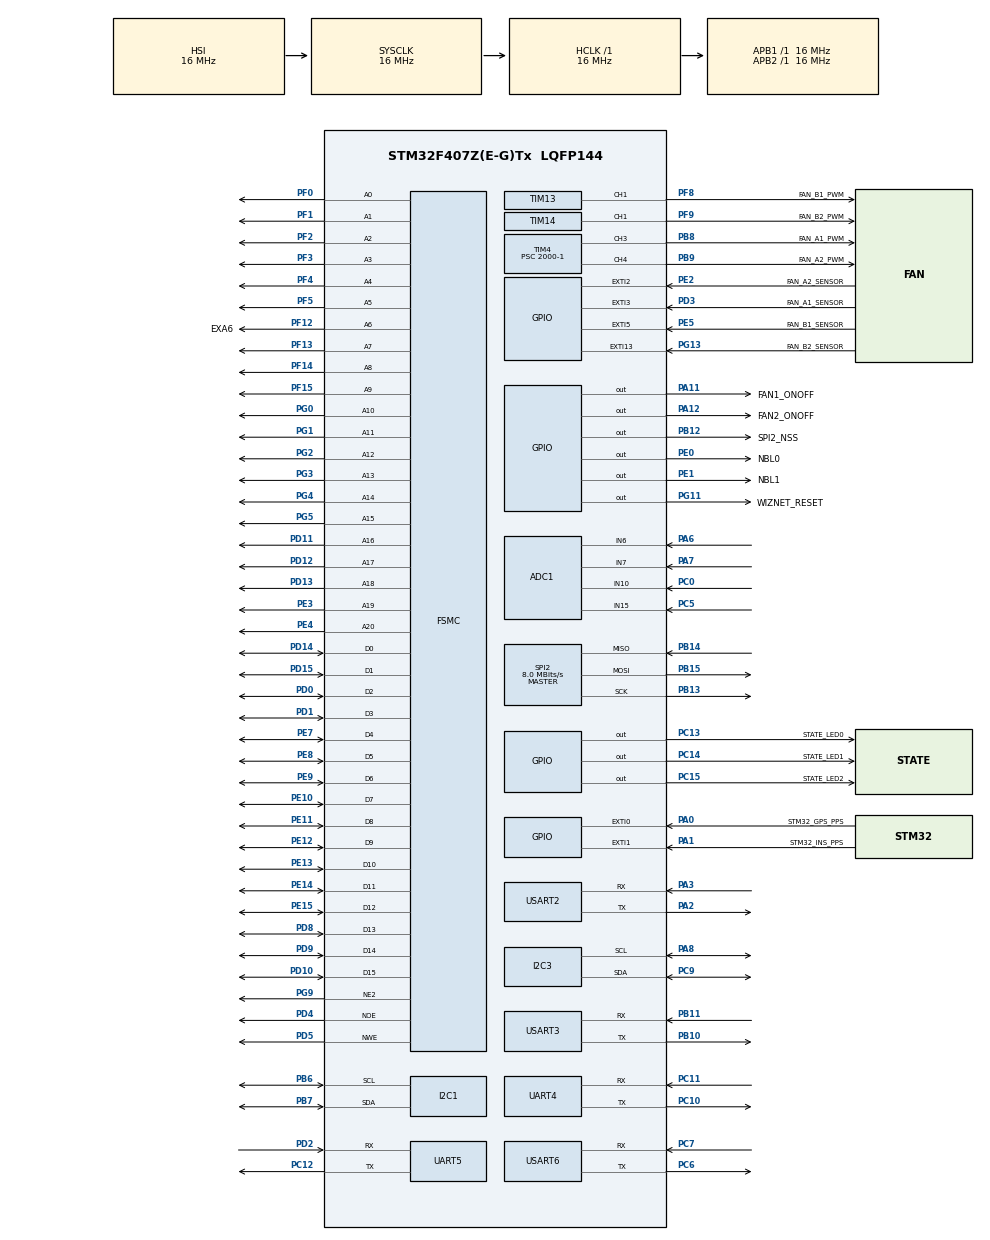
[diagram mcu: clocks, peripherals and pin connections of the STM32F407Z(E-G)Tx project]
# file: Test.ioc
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ADC1.Channel-0\#ChannelRegularConversion=ADC_CHANNEL_TEMPSENSOR
ADC1.Channel-1\#ChannelRegularConversion=ADC_CHANNEL_6
ADC1.Channel-2\#ChannelRegularConversion=ADC_CHANNEL_7
ADC1.Channel-3\#ChannelRegularConversion=ADC_CHANNEL_10
ADC1.Channel-4\#ChannelRegularConversion=ADC_CHANNEL_15
ADC1.ContinuousConvMode=DISABLE
ADC1.DMAContinuousRequests=ENABLE
ADC1.DiscontinuousConvMode=ENABLE
ADC1.NbrOfConversion=5
ADC1.NbrOfConversionFlag=1
ADC1.Rank-0\#ChannelRegularConversion=1
ADC1.Rank-1\#ChannelRegularConversion=2
ADC1.Rank-2\#ChannelRegularConversion=3
ADC1.Rank-3\#ChannelRegularConversion=4
ADC1.Rank-4\#ChannelRegularConversion=5
ADC1.SamplingTime-0\#ChannelRegularConversion=ADC_SAMPLETIME_3CYCLES
ADC1.SamplingTime-1\#ChannelRegularConversion=ADC_SAMPLETIME_3CYCLES
ADC1.SamplingTime-2\#ChannelRegularConversion=ADC_SAMPLETIME_3CYCLES
ADC1.SamplingTime-3\#ChannelRegularConversion=ADC_SAMPLETIME_3CYCLES
ADC1.SamplingTime-4\#ChannelRegularConversion=ADC_SAMPLETIME_3CYCLES
ADC1.ScanConvMode=ENABLE
ADC1.master=1
Dma.ADC1.0.Direction=DMA_PERIPH_TO_MEMORY
Dma.ADC1.0.FIFOMode=DMA_FIFOMODE_DISABLE
Dma.ADC1.0.Instance=DMA2_Stream0
Dma.ADC1.0.MemDataAlignment=DMA_MDATAALIGN_WORD
Dma.ADC1.0.MemInc=DMA_MINC_ENABLE
Dma.ADC1.0.Mode=DMA_CIRCULAR
Dma.ADC1.0.PeriphDataAlignment=DMA_PDATAALIGN_WORD
Dma.ADC1.0.PeriphInc=DMA_PINC_DISABLE
Dma.ADC1.0.Priority=DMA_PRIORITY_LOW
Dma.Request0=ADC1
FSMC.AddressSetupTime2=0
FSMC.BusTurnAroundDuration2=0
FSMC.DataSetupTime2=3
FSMC.WriteOperation2=FSMC_WRITE_OPERATION_ENABLE
I2C1.I2C_Mode=I2C_Standard
Mcu.Family=STM32F4
Mcu.Name=STM32F407Z(E-G)Tx
Mcu.Package=LQFP144
NVIC.DMA2_Stream0_IRQn=true\:0\:0\:false\:false\:true\:false\:true\:true
NVIC.EXTI15_10_IRQn=true\:0\:0\:false\:false\:true\:true\:true\:true
NVIC.EXTI2_IRQn=true\:0\:0\:false\:false\:true\:true\:true\:true
NVIC.EXTI3_IRQn=true\:0\:0\:false\:false\:true\:true\:true\:true
NVIC.EXTI9_5_IRQn=true\:0\:0\:false\:false\:true\:true\:true\:true
NVIC.PriorityGroup=NVIC_PRIORITYGROUP_4
NVIC.USART2_IRQn=true\:0\:0\:false\:false\:true\:true\:true\:true
PA0-WKUP.GPIO_Label=STM32_GPS_PPS
PA0-WKUP.Signal=GPXTI0
PA1.GPIO_Label=STM32_INS_PPS
PA1.Signal=GPXTI1
PA11.GPIO_Label=FAN1_ONOFF
PA11.Signal=GPIO_Output
PA12.GPIO_Label=FAN2_ONOFF
PA12.Signal=GPIO_Output
PA13.Mode=JTAG_5_pins
PA13.Signal=SYS_JTMS-SWDIO
PA14.Mode=JTAG_5_pins
PA14.Signal=SYS_JTCK-SWCLK
PA15.Mode=JTAG_5_pins
PA15.Signal=SYS_JTDI
PA2.Mode=Asynchronous
PA2.Signal=USART2_TX
PA3.Mode=Asynchronous
PA3.Signal=USART2_RX
PA6.Signal=ADCx_IN6
PA7.Signal=ADCx_IN7
PA8.GPIO_Pu=GPIO_PULLUP
PA8.Mode=I2C
PA8.Signal=I2C3_SCL
PB10.Mode=Asynchronous
PB10.Signal=USART3_TX
PB11.Mode=Asynchronous
PB11.Signal=USART3_RX
PB12.GPIO_Label=SPI2_NSS
PB12.Signal=GPIO_Output
PB13.Mode=Full_Duplex_Master
PB13.Signal=SPI2_SCK
PB14.Mode=Full_Duplex_Master
PB14.Signal=SPI2_MISO
PB15.Mode=Full_Duplex_Master
PB15.Signal=SPI2_MOSI
PB3.Mode=JTAG_5_pins
PB3.Signal=SYS_JTDO-SWO
PB4.Mode=JTAG_5_pins
PB4.Signal=SYS_JTRST
PB6.GPIO_Pu=GPIO_PULLUP
PB6.Mode=I2C
PB6.Signal=I2C1_SCL
PB7.GPIO_Pu=GPIO_PULLUP
PB7.Mode=I2C
PB7.Signal=I2C1_SDA
PB8.GPIO_Label=FAN_A1_PWM
PB8.Signal=S_TIM4_CH3
PB9.GPIO_Label=FAN_A2_PWM
PB9.Signal=S_TIM4_CH4
PC0.Signal=ADCx_IN10
PC10.Mode=Asynchronous
PC10.Signal=UART4_TX
PC11.Mode=Asynchronous
PC11.Signal=UART4_RX
PC12.Mode=Asynchronous
PC12.Signal=UART5_TX
PC13-ANTI_TAMP.GPIO_Label=STATE_LED0
PC13-ANTI_TAMP.Signal=GPIO_Output
PC14-OSC32_IN.GPIO_Label=STATE_LED1
PC14-OSC32_IN.Signal=GPIO_Output
PC15-OSC32_OUT.GPIO_Label=STATE_LED2
PC15-OSC32_OUT.Signal=GPIO_Output
PC5.Signal=ADCx_IN15
PC6.Mode=Asynchronous
PC6.Signal=USART6_TX
PC7.Mode=Asynchronous
PC7.Signal=USART6_RX
PC9.GPIO_Pu=GPIO_PULLUP
PC9.Mode=I2C
PC9.Signal=I2C3_SDA
PD0.Signal=FSMC_D2_DA2
PD1.Signal=FSMC_D3_DA3
PD10.Signal=FSMC_D15_DA15
PD11.Signal=FSMC_A16_CLE
PD12.Signal=FSMC_A17_ALE
PD13.Signal=FSMC_A18
PD14.Signal=FSMC_D0_DA0
PD15.Signal=FSMC_D1_DA1
PD2.Mode=Asynchronous
PD2.Signal=UART5_RX
PD3.GPIO_Label=FAN_A1_SENSOR
PD3.Signal=GPXTI3
PD4.Signal=FSMC_NOE
PD5.Signal=FSMC_NWE
PD8.Signal=FSMC_D13_DA13
PD9.Signal=FSMC_D14_DA14
PE0.GPIO_Label=NBL0
PE0.Signal=GPIO_Output
PE1.GPIO_Label=NBL1
PE1.Signal=GPIO_Output
PE10.Signal=FSMC_D7_DA7
PE11.Signal=FSMC_D8_DA8
PE12.Signal=FSMC_D9_DA9
PE13.Signal=FSMC_D10_DA10
PE14.Signal=FSMC_D11_DA11
PE15.Signal=FSMC_D12_DA12
PE2.GPIO_Label=FAN_A2_SENSOR
PE2.Signal=GPXTI2
PE3.Signal=FSMC_A19
PE4.Signal=FSMC_A20
PE5.GPIO_Label=FAN_B1_SENSOR
PE5.Signal=GPXTI5
PE7.Signal=FSMC_D4_DA4
PE8.Signal=FSMC_D5_DA5
PE9.Signal=FSMC_D6_DA6
PF0.Signal=FSMC_A0
PF1.Signal=FSMC_A1
PF12.GPIO_Label=EXA6
PF12.Signal=FSMC_A6
PF13.Signal=FSMC_A7
PF14.Signal=FSMC_A8
PF15.Signal=FSMC_A9
PF2.Signal=FSMC_A2
PF3.Signal=FSMC_A3
PF4.Signal=FSMC_A4
PF5.Signal=FSMC_A5
PF8.GPIO_Label=FAN_B1_PWM
PF8.Signal=S_TIM13_CH1
PF9.GPIO_Label=FAN_B2_PWM
PF9.Signal=S_TIM14_CH1
PG0.Signal=FSMC_A10
PG1.Signal=FSMC_A11
PG11.GPIO_Label=WIZNET_RESET
PG11.PinState=GPIO_PIN_SET
PG11.Signal=GPIO_Output
PG13.GPIO_Label=FAN_B2_SENSOR
PG13.Signal=GPXTI13
PG2.Signal=FSMC_A12
PG3.Signal=FSMC_A13
PG4.Signal=FSMC_A14
PG5.Signal=FSMC_A15
PG9.Mode=NorPsramChipSelect2_2
PG9.Signal=FSMC_NE2
PH0-OSC_IN.Mode=HSE-External-Oscillator
PH0-OSC_IN.Signal=RCC_OSC_IN
PH1-OSC_OUT.Mode=HSE-External-Oscillator
PH1-OSC_OUT.Signal=RCC_OSC_OUT
ProjectManager.HeapSize=0x200
ProjectManager.StackSize=0x400
ProjectManager.TargetToolchain=EWARM V8.32
RCC.48MHZClocksFreq_Value=32000000
RCC.AHBFreq_Value=16000000
RCC.APB1Freq_Value=16000000
RCC.APB1TimFreq_Value=16000000
RCC.APB2Freq_Value=16000000
RCC.APB2TimFreq_Value=16000000
RCC.CortexFreq_Value=16000000
RCC.HCLKFreq_Value=16000000
RCC.HSE_VALUE=25000000
RCC.HSI_VALUE=16000000
RCC.LSE_VALUE=32768
RCC.PLLM=8
RCC.PLLN=64
RCC.SYSCLKFreq_VALUE=16000000
RCC.VCOOutputFreq_Value=128000000
SH.ADCx_IN10.0=ADC1_IN10,IN10
SH.ADCx_IN15.0=ADC1_IN15,IN15
SH.ADCx_IN6.0=ADC1_IN6,IN6
SH.ADCx_IN7.0=ADC1_IN7,IN7
SH.FSMC_A0.0=FSMC_A0,21b-a2
SH.FSMC_A1.0=FSMC_A1,21b-a2
SH.FSMC_A10.0=FSMC_A10,21b-a2
SH.FSMC_A11.0=FSMC_A11,21b-a2
SH.FSMC_A12.0=FSMC_A12,21b-a2
SH.FSMC_A13.0=FSMC_A13,21b-a2
SH.FSMC_A14.0=FSMC_A14,21b-a2
SH.FSMC_A15.0=FSMC_A15,21b-a2
SH.FSMC_A16_CLE.0=FSMC_A16,21b-a2
SH.FSMC_A17_ALE.0=FSMC_A17,21b-a2
SH.FSMC_A18.0=FSMC_A18,21b-a2
SH.FSMC_A19.0=FSMC_A19,21b-a2
SH.FSMC_A2.0=FSMC_A2,21b-a2
SH.FSMC_A20.0=FSMC_A20,21b-a2
SH.FSMC_A3.0=FSMC_A3,21b-a2
SH.FSMC_A4.0=FSMC_A4,21b-a2
SH.FSMC_A5.0=FSMC_A5,21b-a2
SH.FSMC_A6.0=FSMC_A6,21b-a2
SH.FSMC_A7.0=FSMC_A7,21b-a2
SH.FSMC_A8.0=FSMC_A8,21b-a2
SH.FSMC_A9.0=FSMC_A9,21b-a2
SH.FSMC_D0_DA0.0=FSMC_D0,16b-d2
SH.FSMC_D10_DA10.0=FSMC_D10,16b-d2
SH.FSMC_D11_DA11.0=FSMC_D11,16b-d2
SH.FSMC_D12_DA12.0=FSMC_D12,16b-d2
SH.FSMC_D13_DA13.0=FSMC_D13,16b-d2
SH.FSMC_D14_DA14.0=FSMC_D14,16b-d2
SH.FSMC_D15_DA15.0=FSMC_D15,16b-d2
SH.FSMC_D1_DA1.0=FSMC_D1,16b-d2
SH.FSMC_D2_DA2.0=FSMC_D2,16b-d2
SH.FSMC_D3_DA3.0=FSMC_D3,16b-d2
SH.FSMC_D4_DA4.0=FSMC_D4,16b-d2
SH.FSMC_D5_DA5.0=FSMC_D5,16b-d2
SH.FSMC_D6_DA6.0=FSMC_D6,16b-d2
SH.FSMC_D7_DA7.0=FSMC_D7,16b-d2
SH.FSMC_D8_DA8.0=FSMC_D8,16b-d2
SH.FSMC_D9_DA9.0=FSMC_D9,16b-d2
SH.FSMC_NOE.0=FSMC_NOE,Sram2
SH.FSMC_NWE.0=FSMC_NWE,Sram2
SH.S_TIM13_CH1.0=TIM13_CH1,PWM Generation1 CH1
SH.S_TIM14_CH1.0=TIM14_CH1,PWM Generation1 CH1
SH.S_TIM4_CH3.0=TIM4_CH3,PWM Generation3 CH3
SH.S_TIM4_CH4.0=TIM4_CH4,PWM Generation4 CH4
SPI2.CalculateBaudRate=8.0 MBits/s
SPI2.Direction=SPI_DIRECTION_2LINES
SPI2.Mode=SPI_MODE_MASTER
SPI2.VirtualType=VM_MASTER
TIM13.Channel=TIM_CHANNEL_1
TIM13.Period=1000-1
TIM13.Prescaler=2000-1
TIM13.Pulse=900-1
TIM14.Channel=TIM_CHANNEL_1
TIM14.Period=1000-1
TIM14.Prescaler=2000-1
TIM14.Pulse=900-1
TIM4.Channel-PWM\ Generation3\ CH3=TIM_CHANNEL_3
TIM4.Channel-PWM\ Generation4\ CH4=TIM_CHANNEL_4
TIM4.Period=1000-1
TIM4.Prescaler=2000-1
TIM4.Pulse-PWM\ Generation3\ CH3=900-1
TIM4.Pulse-PWM\ Generation4\ CH4=900-1
TIM6.Period=1000-1
TIM6.Prescaler=16000-1
UART4.VirtualMode=Asynchronous
UART5.VirtualMode=Asynchronous
USART2.VirtualMode=VM_ASYNC
USART3.VirtualMode=VM_ASYNC
USART6.VirtualMode=VM_ASYNC
VP_ADC1_TempSens_Input.Mode=IN-TempSens
VP_TIM13_VS_ClockSourceINT.Mode=Enable_Timer
VP_TIM14_VS_ClockSourceINT.Mode=Enable_Timer
VP_TIM4_VS_ClockSourceINT.Mode=Internal
VP_TIM6_VS_ClockSourceINT.Mode=Enable_Timer
board=custom

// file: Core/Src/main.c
/* USER CODE BEGIN Header */
/**
******************************************************************************
* @file           : main.c
* @brief          : Main program body
******************************************************************************
* @attention
*
* Copyright (c) 2022 STMicroelectronics.
* All rights reserved.
*
* This software is licensed under terms that can be found in the LICENSE file
* in the root directory of this software component.
* If no LICENSE file comes with this software, it is provided AS-IS.
*
******************************************************************************
*/
/* USER CODE END Header */
#include "main.h"

/* USER CODE BEGIN Includes */
#include "math.h"
#include "stdio.h"
/* USER CODE END Includes */

/* USER CODE BEGIN PD */

#define TSYS01_ADDR                        0x77
#define TSYS01_RESET                       0x1E
#define TSYS01_ADC_READ                    0x00
#define TSYS01_ADC_TEMP_CONV               0x48
#define TSYS01_PROM_READ                   0XA0

#define RPM_Calculation                 60000

/* USER CODE END PD */

ADC_HandleTypeDef hadc1;
DMA_HandleTypeDef hdma_adc1;

I2C_HandleTypeDef hi2c1;
I2C_HandleTypeDef hi2c3;

SPI_HandleTypeDef hspi2;

TIM_HandleTypeDef htim4;
TIM_HandleTypeDef htim6;
TIM_HandleTypeDef htim13;
TIM_HandleTypeDef htim14;

UART_HandleTypeDef huart4;
UART_HandleTypeDef huart5;
UART_HandleTypeDef huart2;
UART_HandleTypeDef huart3;
UART_HandleTypeDef huart6;

SRAM_HandleTypeDef hsram2;

void SystemClock_Config(void);
static void MX_GPIO_Init(void);
static void MX_DMA_Init(void);
static void MX_I2C3_Init(void);
static void MX_UART4_Init(void);
static void MX_UART5_Init(void);
static void MX_USART2_UART_Init(void);
static void MX_USART3_UART_Init(void);
static void MX_USART6_UART_Init(void);
static void MX_SPI2_Init(void);
static void MX_I2C1_Init(void);
static void MX_TIM4_Init(void);
static void MX_FSMC_Init(void);
static void MX_TIM13_Init(void);
static void MX_TIM14_Init(void);
static void MX_TIM6_Init(void);
static void MX_ADC1_Init(void);

/* USER CODE BEGIN 0 */

//prinf() UART out
int fputc(int ch,  FILE *f){

  HAL_UART_Transmit(&huart2,(uint8_t*)&ch,1,1);

  return ch;

}

//temperature sensor
float temperature_f1 =0.0;
float temperature_f2 =0.0;

//uart
uint8_t USART_RX_FLAG = 0;
uint8_t temp_rx =0;

typedef struct{
  uint16_t TIMER_DATA1;
  uint16_t TIMER_DATA2;
  uint16_t TIMER_MINU;
  uint16_t FAN_RPM;
  uint8_t  RPM_check;
}TIMER_struct;

typedef struct{
  float ADC_TEMP_C;
  float ADC_FAN1_VOL;
  float ADC_FAN2_VOL;
  float ADC_3_3V_VOL;
  float ADC_12V2_VOL;
}ADC_CAL_struct;

ADC_CAL_struct ADC_cal;

TIMER_struct A1_DATA;
TIMER_struct A2_DATA;
TIMER_struct B1_DATA;
TIMER_struct B2_DATA;

void TIMER_struct_init(TIMER_struct* DATA){
  DATA->TIMER_DATA1=0;
  DATA->TIMER_DATA2=0;
  DATA->TIMER_MINU=0;
  DATA->FAN_RPM=0;
  DATA->RPM_check=1;

}

void TIMER_RPM(TIMER_struct* DATA){

  if(DATA->RPM_check == 1){
    DATA->TIMER_DATA1=htim6.Instance->CNT;
    DATA->RPM_check++;
  }
  else if (DATA->RPM_check == 2){
    DATA->RPM_check++;
  }
  else if (DATA->RPM_check == 3){
    DATA->TIMER_DATA2=htim6.Instance->CNT;

    if(DATA->TIMER_DATA2 < DATA->TIMER_DATA1) DATA->TIMER_DATA2+=1000;

    DATA->TIMER_MINU =  DATA->TIMER_DATA2 - DATA->TIMER_DATA1;
    DATA->FAN_RPM = RPM_Calculation / DATA->TIMER_MINU;

    DATA->RPM_check=1;
  }

}
uint8_t i2c_rx[4];
double TEST_I2C(){
  uint8_t i2c_tx= 0x00;

  HAL_I2C_Master_Transmit(&hi2c1,0x80,&i2c_tx,1,100);
  HAL_Delay(1000);
  HAL_I2C_Master_Transmit(&hi2c3,0x80,&i2c_tx,1,100);
  HAL_Delay(1000);
  return 0.0;
}
double I2C_Temperature(I2C_HandleTypeDef *hi2c){

  uint8_t adc_read[5]={0};
  uint8_t adc_k2[2]={0};
  uint8_t adc_k3[2]={0};
  uint8_t adc_k4[2]={0};
  uint8_t adc_k1[2]={0};
  uint8_t adc_k0[2]={0};

  uint16_t adc_Coefficient[5]={0};
  uint64_t adc_data=0;

  uint16_t adc_read_addr = TSYS01_ADC_READ;
  uint16_t adc_prom_read = TSYS01_PROM_READ;
  uint8_t adc_start_addr = TSYS01_ADC_TEMP_CONV;

  double temperature_d = 0.0;
  HAL_I2C_Master_Transmit(hi2c,TSYS01_ADDR<<1,&adc_start_addr,1,100);

  HAL_Delay(10);
  HAL_I2C_Mem_Read(hi2c,TSYS01_ADDR<<1,adc_read_addr,1,adc_read,3,100);
  HAL_Delay(10);
  adc_data = 0;
  adc_data = adc_read[0];
  adc_data = (adc_data << 8) | adc_read[1];
  adc_data = (adc_data << 8) | adc_read[2];

  adc_data= adc_data/256;

  HAL_I2C_Mem_Read(hi2c,TSYS01_ADDR<<1,adc_prom_read+2,1,adc_k4,2,100);
  HAL_Delay(10);

  HAL_I2C_Mem_Read(hi2c,TSYS01_ADDR<<1,adc_prom_read+4,1,adc_k3,2,100);
  HAL_Delay(10);

  HAL_I2C_Mem_Read(hi2c,TSYS01_ADDR<<1,adc_prom_read+6,1,adc_k2,2,100);
  HAL_Delay(10);

  HAL_I2C_Mem_Read(hi2c,TSYS01_ADDR<<1,adc_prom_read+8,1,adc_k1,2,100);
  HAL_Delay(10);

  HAL_I2C_Mem_Read(hi2c,TSYS01_ADDR<<1,adc_prom_read+10,1,adc_k0,2,100);
  HAL_Delay(10);

  adc_Coefficient[0] = (uint16_t)((adc_k4[0] << 8) + adc_k4[1]);
  adc_Coefficient[1] = (uint16_t)((adc_k3[0] << 8) + adc_k3[1]);
  adc_Coefficient[2] = (uint16_t)((adc_k2[0] << 8) + adc_k2[1]);
  adc_Coefficient[3] = (uint16_t)((adc_k1[0] << 8) + adc_k1[1]);
  adc_Coefficient[4] = (uint16_t)((adc_k0[0] << 8) + adc_k0[1]);

  temperature_d = ((-2)*adc_Coefficient[0]/pow(10,21)*pow(adc_data,4))\
    +((4)*adc_Coefficient[1]/pow(10,16)*pow(adc_data,3))\
      +((-2)*adc_Coefficient[2]/pow(10,11)*pow(adc_data,2))\
        +((1)*adc_Coefficient[3]/pow(10,6)*adc_data)\
          +((-1.5)*adc_Coefficient[4]/pow(10,2));

  return temperature_d;

}

void HAL_GPIO_EXTI_Callback(uint16_t GPIO_Pin){

  //FAN_A1_SENSOR
  if(GPIO_Pin == GPIO_PIN_3){
    HAL_GPIO_TogglePin(GPIOC,STATE_LED0_Pin);
    TIMER_RPM(&A1_DATA);

  }
  //FAN_A2_SENSOR
  else if(GPIO_Pin == GPIO_PIN_2){
    TIMER_RPM(&A2_DATA);

  }
  //FAN_B1_SENSOR
  else if(GPIO_Pin == GPIO_PIN_5){
    TIMER_RPM(&B1_DATA);

  }
  //FAN_B2_SENSOR
  else if(GPIO_Pin == GPIO_PIN_13){
    TIMER_RPM(&B2_DATA);

  }
}
void HAL_UART_RxCpltCallback(UART_HandleTypeDef *huart)
{

  // USART1 Rx Interrupt
  if (huart->Instance == USART2) {

    if(temp_rx == '1'){
      USART_RX_FLAG =1;
    }
    else if(temp_rx == '2'){
      USART_RX_FLAG = 2;
    }

    HAL_UART_Receive_IT(&huart2, &temp_rx, 1);
  }
}
void HAL_TIM_PeriodElapsedCallback(TIM_HandleTypeDef *htim){
  if(htim->Instance == TIM6){

  }
}

uint32_t adcVal[5];

uint8_t adcIndex=0;
uint8_t adc_conv_flag = 0;
float temp1;

void ADC_Calculation(){

  ADC_cal.ADC_TEMP_C   = ((((float)adcVal[0] * 3.3) / 4096) - 0.76)/0.0025 + 25.0;
  ADC_cal.ADC_FAN1_VOL = ((float)adcVal[1] * 3.3 / 4096);
  ADC_cal.ADC_FAN2_VOL = ((float)adcVal[2] * 3.3 / 4096);
  ADC_cal.ADC_3_3V_VOL = ((float)adcVal[3] * 3.3 / 4096);
  ADC_cal.ADC_12V2_VOL = ((float)adcVal[4] * 3.3 / 4096);

}
void HAL_ADC_ConvCpltCallback(ADC_HandleTypeDef* hadc)
{

  ADC_Calculation();

}

/* USER CODE END 0 */

int main(void)
{

  /* MCU Configuration--------------------------------------------------------*/

  /* Reset of all peripherals, Initializes the Flash interface and the Systick. */
  HAL_Init();

  /* Configure the system clock */
  SystemClock_Config();

  /* Initialize all configured peripherals */
  MX_GPIO_Init();
  MX_DMA_Init();
  MX_I2C3_Init();
  MX_UART4_Init();
  MX_UART5_Init();
  MX_USART2_UART_Init();
  MX_USART3_UART_Init();
  MX_USART6_UART_Init();
  MX_SPI2_Init();
  MX_I2C1_Init();
  MX_TIM4_Init();
  MX_FSMC_Init();
  MX_TIM13_Init();
  MX_TIM14_Init();
  MX_TIM6_Init();
  MX_ADC1_Init();
  /* USER CODE BEGIN 2 */
  HAL_UART_Receive_IT(&huart2, &temp_rx, 1);
  /* USER CODE END 2 */

  /* Infinite loop */
  /* USER CODE BEGIN WHILE */

  uint8_t i2c_reset = 0x1E;

  TIMER_struct_init(&A1_DATA);
  TIMER_struct_init(&A2_DATA);
  TIMER_struct_init(&B1_DATA);
  TIMER_struct_init(&B2_DATA);

  // FAN2 Connecter start
  HAL_TIM_PWM_Start(&htim14, TIM_CHANNEL_1);
  HAL_TIM_PWM_Start(&htim13, TIM_CHANNEL_1);

  HAL_GPIO_WritePin(GPIOA,FAN2_ONOFF_Pin,GPIO_PIN_SET);

  //FAN1 Connecter start
  HAL_TIM_PWM_Start(&htim4, TIM_CHANNEL_3);
  HAL_TIM_PWM_Start(&htim4, TIM_CHANNEL_4);

  HAL_GPIO_WritePin(GPIOA,FAN1_ONOFF_Pin,GPIO_PIN_SET);

  //rpm data calculation timer
  HAL_TIM_Base_Start_IT(&htim6) ;

  //HAL_I2C_Master_Transmit(&hi2c3,TSYS01_ADDR<<1,&i2c_reset,1,100);
  HAL_Delay(10);

  while (1)
  {

    HAL_ADC_Start_DMA(&hadc1,adcVal,5);

    //temperature_f1 = I2C_Temperature(&hi2c3);
    temperature_f2 = TEST_I2C();

    if(temperature_f1 > 30){
      htim4.Instance->CCR3 = 500-1;
      htim4.Instance->CCR4 = 500-1;
    }
    else {
      htim4.Instance->CCR3 = 900-1;
      htim4.Instance->CCR4 = 900-1;
    }

    if(USART_RX_FLAG == 1){
      printf("$TEMP,1,%.2f,2,%.2f,uart,0\r\n",temperature_f1,temperature_f2);
      printf("$RPM,A1,%d,A2,%d,B1,%d,B2,%d,uart,1\r\n",A1_DATA.FAN_RPM,A2_DATA.FAN_RPM,B1_DATA.FAN_RPM,B2_DATA.FAN_RPM);
      printf("$ADC,temp,%.2f,FAN1,%.2f,FAN2,%.2f,3.3V,%.2f,12V,%.2f,uart,3\r\n",ADC_cal.ADC_TEMP_C,\
                                                                                ADC_cal.ADC_FAN1_VOL,ADC_cal.ADC_FAN2_VOL,ADC_cal.ADC_3_3V_VOL,ADC_cal.ADC_12V2_VOL);
      HAL_Delay(1000);

    }
    else if(USART_RX_FLAG == 2){
      printf("temp : %5.1f \r\n",temp1);
      HAL_Delay(1000);

    }
    /* USER CODE END WHILE */

  }
}

void SystemClock_Config(void)
{
  RCC_OscInitTypeDef RCC_OscInitStruct = {0};
  RCC_ClkInitTypeDef RCC_ClkInitStruct = {0};

  /** Configure the main internal regulator output voltage
  */
  __HAL_RCC_PWR_CLK_ENABLE();
  __HAL_PWR_VOLTAGESCALING_CONFIG(PWR_REGULATOR_VOLTAGE_SCALE1);

  /** Initializes the RCC Oscillators according to the specified parameters
  * in the RCC_OscInitTypeDef structure.
  */
  RCC_OscInitStruct.OscillatorType = RCC_OSCILLATORTYPE_HSI;
  RCC_OscInitStruct.HSIState = RCC_HSI_ON;
  RCC_OscInitStruct.HSICalibrationValue = RCC_HSICALIBRATION_DEFAULT;
  RCC_OscInitStruct.PLL.PLLState = RCC_PLL_NONE;
  if (HAL_RCC_OscConfig(&RCC_OscInitStruct) != HAL_OK)
  {
    Error_Handler();
  }

  /** Initializes the CPU, AHB and APB buses clocks
  */
  RCC_ClkInitStruct.ClockType = RCC_CLOCKTYPE_HCLK|RCC_CLOCKTYPE_SYSCLK
                              |RCC_CLOCKTYPE_PCLK1|RCC_CLOCKTYPE_PCLK2;
  RCC_ClkInitStruct.SYSCLKSource = RCC_SYSCLKSOURCE_HSI;
  RCC_ClkInitStruct.AHBCLKDivider = RCC_SYSCLK_DIV1;
  RCC_ClkInitStruct.APB1CLKDivider = RCC_HCLK_DIV1;
  RCC_ClkInitStruct.APB2CLKDivider = RCC_HCLK_DIV1;

  if (HAL_RCC_ClockConfig(&RCC_ClkInitStruct, FLASH_LATENCY_0) != HAL_OK)
  {
    Error_Handler();
  }
}

static void MX_ADC1_Init(void)
{

  ADC_ChannelConfTypeDef sConfig = {0};

  /** Configure the global features of the ADC (Clock, Resolution, Data Alignment and number of conversion)
  */
  hadc1.Instance = ADC1;
  hadc1.Init.ClockPrescaler = ADC_CLOCK_SYNC_PCLK_DIV2;
  hadc1.Init.Resolution = ADC_RESOLUTION_12B;
  hadc1.Init.ScanConvMode = ENABLE;
  hadc1.Init.ContinuousConvMode = DISABLE;
  hadc1.Init.DiscontinuousConvMode = ENABLE;
  hadc1.Init.NbrOfDiscConversion = 1;
  hadc1.Init.ExternalTrigConvEdge = ADC_EXTERNALTRIGCONVEDGE_NONE;
  hadc1.Init.ExternalTrigConv = ADC_SOFTWARE_START;
  hadc1.Init.DataAlign = ADC_DATAALIGN_RIGHT;
  hadc1.Init.NbrOfConversion = 5;
  hadc1.Init.DMAContinuousRequests = ENABLE;
  hadc1.Init.EOCSelection = ADC_EOC_SINGLE_CONV;
  if (HAL_ADC_Init(&hadc1) != HAL_OK)
  {
    Error_Handler();
  }

  /** Configure for the selected ADC regular channel its corresponding rank in the sequencer and its sample time.
  */
  sConfig.Channel = ADC_CHANNEL_TEMPSENSOR;
  sConfig.Rank = 1;
  sConfig.SamplingTime = ADC_SAMPLETIME_3CYCLES;
  if (HAL_ADC_ConfigChannel(&hadc1, &sConfig) != HAL_OK)
  {
    Error_Handler();
  }

  /** Configure for the selected ADC regular channel its corresponding rank in the sequencer and its sample time.
  */
  sConfig.Channel = ADC_CHANNEL_6;
  sConfig.Rank = 2;
  if (HAL_ADC_ConfigChannel(&hadc1, &sConfig) != HAL_OK)
  {
    Error_Handler();
  }

  /** Configure for the selected ADC regular channel its corresponding rank in the sequencer and its sample time.
  */
  sConfig.Channel = ADC_CHANNEL_7;
  sConfig.Rank = 3;
  if (HAL_ADC_ConfigChannel(&hadc1, &sConfig) != HAL_OK)
  {
    Error_Handler();
  }

  /** Configure for the selected ADC regular channel its corresponding rank in the sequencer and its sample time.
  */
  sConfig.Channel = ADC_CHANNEL_10;
  sConfig.Rank = 4;
  if (HAL_ADC_ConfigChannel(&hadc1, &sConfig) != HAL_OK)
  {
    Error_Handler();
  }

  /** Configure for the selected ADC regular channel its corresponding rank in the sequencer and its sample time.
  */
  sConfig.Channel = ADC_CHANNEL_15;
  sConfig.Rank = 5;
  if (HAL_ADC_ConfigChannel(&hadc1, &sConfig) != HAL_OK)
  {
    Error_Handler();
  }

}

static void MX_I2C1_Init(void)
{

  hi2c1.Instance = I2C1;
  hi2c1.Init.ClockSpeed = 100000;
  hi2c1.Init.DutyCycle = I2C_DUTYCYCLE_2;
  hi2c1.Init.OwnAddress1 = 0;
  hi2c1.Init.AddressingMode = I2C_ADDRESSINGMODE_7BIT;
  hi2c1.Init.DualAddressMode = I2C_DUALADDRESS_DISABLE;
  hi2c1.Init.OwnAddress2 = 0;
  hi2c1.Init.GeneralCallMode = I2C_GENERALCALL_DISABLE;
  hi2c1.Init.NoStretchMode = I2C_NOSTRETCH_DISABLE;
  if (HAL_I2C_Init(&hi2c1) != HAL_OK)
  {
    Error_Handler();
  }

}

static void MX_I2C3_Init(void)
{

  hi2c3.Instance = I2C3;
  hi2c3.Init.ClockSpeed = 100000;
  hi2c3.Init.DutyCycle = I2C_DUTYCYCLE_2;
  hi2c3.Init.OwnAddress1 = 0;
  hi2c3.Init.AddressingMode = I2C_ADDRESSINGMODE_7BIT;
  hi2c3.Init.DualAddressMode = I2C_DUALADDRESS_DISABLE;
  hi2c3.Init.OwnAddress2 = 0;
  hi2c3.Init.GeneralCallMode = I2C_GENERALCALL_DISABLE;
  hi2c3.Init.NoStretchMode = I2C_NOSTRETCH_DISABLE;
  if (HAL_I2C_Init(&hi2c3) != HAL_OK)
  {
    Error_Handler();
  }

}

static void MX_SPI2_Init(void)
{

  /* SPI2 parameter configuration*/
  hspi2.Instance = SPI2;
  hspi2.Init.Mode = SPI_MODE_MASTER;
  hspi2.Init.Direction = SPI_DIRECTION_2LINES;
  hspi2.Init.DataSize = SPI_DATASIZE_8BIT;
  hspi2.Init.CLKPolarity = SPI_POLARITY_LOW;
  hspi2.Init.CLKPhase = SPI_PHASE_1EDGE;
  hspi2.Init.NSS = SPI_NSS_SOFT;
  hspi2.Init.BaudRatePrescaler = SPI_BAUDRATEPRESCALER_2;
  hspi2.Init.FirstBit = SPI_FIRSTBIT_MSB;
  hspi2.Init.TIMode = SPI_TIMODE_DISABLE;
  hspi2.Init.CRCCalculation = SPI_CRCCALCULATION_DISABLE;
  hspi2.Init.CRCPolynomial = 10;
  if (HAL_SPI_Init(&hspi2) != HAL_OK)
  {
    Error_Handler();
  }

}

static void MX_TIM4_Init(void)
{

  TIM_ClockConfigTypeDef sClockSourceConfig = {0};
  TIM_MasterConfigTypeDef sMasterConfig = {0};
  TIM_OC_InitTypeDef sConfigOC = {0};

  htim4.Instance = TIM4;
  htim4.Init.Prescaler = 2000-1;
  htim4.Init.CounterMode = TIM_COUNTERMODE_UP;
  htim4.Init.Period = 1000-1;
  htim4.Init.ClockDivision = TIM_CLOCKDIVISION_DIV1;
  htim4.Init.AutoReloadPreload = TIM_AUTORELOAD_PRELOAD_DISABLE;
  if (HAL_TIM_Base_Init(&htim4) != HAL_OK)
  {
    Error_Handler();
  }
  sClockSourceConfig.ClockSource = TIM_CLOCKSOURCE_INTERNAL;
  if (HAL_TIM_ConfigClockSource(&htim4, &sClockSourceConfig) != HAL_OK)
  {
    Error_Handler();
  }
  if (HAL_TIM_PWM_Init(&htim4) != HAL_OK)
  {
    Error_Handler();
  }
  sMasterConfig.MasterOutputTrigger = TIM_TRGO_RESET;
  sMasterConfig.MasterSlaveMode = TIM_MASTERSLAVEMODE_DISABLE;
  if (HAL_TIMEx_MasterConfigSynchronization(&htim4, &sMasterConfig) != HAL_OK)
  {
    Error_Handler();
  }
  sConfigOC.OCMode = TIM_OCMODE_PWM1;
  sConfigOC.Pulse = 900-1;
  sConfigOC.OCPolarity = TIM_OCPOLARITY_HIGH;
  sConfigOC.OCFastMode = TIM_OCFAST_DISABLE;
  if (HAL_TIM_PWM_ConfigChannel(&htim4, &sConfigOC, TIM_CHANNEL_3) != HAL_OK)
  {
    Error_Handler();
  }
  if (HAL_TIM_PWM_ConfigChannel(&htim4, &sConfigOC, TIM_CHANNEL_4) != HAL_OK)
  {
    Error_Handler();
  }
  HAL_TIM_MspPostInit(&htim4);

}

static void MX_TIM6_Init(void)
{

  TIM_MasterConfigTypeDef sMasterConfig = {0};

  htim6.Instance = TIM6;
  htim6.Init.Prescaler = 16000-1;
  htim6.Init.CounterMode = TIM_COUNTERMODE_UP;
  htim6.Init.Period = 1000-1;
  htim6.Init.AutoReloadPreload = TIM_AUTORELOAD_PRELOAD_DISABLE;
  if (HAL_TIM_Base_Init(&htim6) != HAL_OK)
  {
    Error_Handler();
  }
  sMasterConfig.MasterOutputTrigger = TIM_TRGO_RESET;
  sMasterConfig.MasterSlaveMode = TIM_MASTERSLAVEMODE_DISABLE;
  if (HAL_TIMEx_MasterConfigSynchronization(&htim6, &sMasterConfig) != HAL_OK)
  {
    Error_Handler();
  }

}

static void MX_TIM13_Init(void)
{

  TIM_OC_InitTypeDef sConfigOC = {0};

  htim13.Instance = TIM13;
  htim13.Init.Prescaler = 2000-1;
  htim13.Init.CounterMode = TIM_COUNTERMODE_UP;
  htim13.Init.Period = 1000-1;
  htim13.Init.ClockDivision = TIM_CLOCKDIVISION_DIV1;
  htim13.Init.AutoReloadPreload = TIM_AUTORELOAD_PRELOAD_DISABLE;
  if (HAL_TIM_Base_Init(&htim13) != HAL_OK)
  {
    Error_Handler();
  }
  if (HAL_TIM_PWM_Init(&htim13) != HAL_OK)
  {
    Error_Handler();
  }
  sConfigOC.OCMode = TIM_OCMODE_PWM1;
  sConfigOC.Pulse = 900-1;
  sConfigOC.OCPolarity = TIM_OCPOLARITY_HIGH;
  sConfigOC.OCFastMode = TIM_OCFAST_DISABLE;
  if (HAL_TIM_PWM_ConfigChannel(&htim13, &sConfigOC, TIM_CHANNEL_1) != HAL_OK)
  {
    Error_Handler();
  }
  HAL_TIM_MspPostInit(&htim13);

}

static void MX_TIM14_Init(void)
{

  TIM_OC_InitTypeDef sConfigOC = {0};

  htim14.Instance = TIM14;
  htim14.Init.Prescaler = 2000-1;
  htim14.Init.CounterMode = TIM_COUNTERMODE_UP;
  htim14.Init.Period = 1000-1;
  htim14.Init.ClockDivision = TIM_CLOCKDIVISION_DIV1;
  htim14.Init.AutoReloadPreload = TIM_AUTORELOAD_PRELOAD_DISABLE;
  if (HAL_TIM_Base_Init(&htim14) != HAL_OK)
  {
    Error_Handler();
  }
  if (HAL_TIM_PWM_Init(&htim14) != HAL_OK)
  {
    Error_Handler();
  }
  sConfigOC.OCMode = TIM_OCMODE_PWM1;
  sConfigOC.Pulse = 900-1;
  sConfigOC.OCPolarity = TIM_OCPOLARITY_HIGH;
  sConfigOC.OCFastMode = TIM_OCFAST_DISABLE;
  if (HAL_TIM_PWM_ConfigChannel(&htim14, &sConfigOC, TIM_CHANNEL_1) != HAL_OK)
  {
    Error_Handler();
  }
  HAL_TIM_MspPostInit(&htim14);

}

static void MX_UART4_Init(void)
{

  huart4.Instance = UART4;
  huart4.Init.BaudRate = 115200;
  huart4.Init.WordLength = UART_WORDLENGTH_8B;
  huart4.Init.StopBits = UART_STOPBITS_1;
  huart4.Init.Parity = UART_PARITY_NONE;
  huart4.Init.Mode = UART_MODE_TX_RX;
  huart4.Init.HwFlowCtl = UART_HWCONTROL_NONE;
  huart4.Init.OverSampling = UART_OVERSAMPLING_16;
  if (HAL_UART_Init(&huart4) != HAL_OK)
  {
    Error_Handler();
  }

}

static void MX_UART5_Init(void)
{

  huart5.Instance = UART5;
  huart5.Init.BaudRate = 115200;
  huart5.Init.WordLength = UART_WORDLENGTH_8B;
  huart5.Init.StopBits = UART_STOPBITS_1;
  huart5.Init.Parity = UART_PARITY_NONE;
  huart5.Init.Mode = UART_MODE_TX_RX;
  huart5.Init.HwFlowCtl = UART_HWCONTROL_NONE;
  huart5.Init.OverSampling = UART_OVERSAMPLING_16;
  if (HAL_UART_Init(&huart5) != HAL_OK)
  {
    Error_Handler();
  }

}

static void MX_USART2_UART_Init(void)
{

  huart2.Instance = USART2;
  huart2.Init.BaudRate = 115200;
  huart2.Init.WordLength = UART_WORDLENGTH_8B;
  huart2.Init.StopBits = UART_STOPBITS_1;
  huart2.Init.Parity = UART_PARITY_NONE;
  huart2.Init.Mode = UART_MODE_TX_RX;
  huart2.Init.HwFlowCtl = UART_HWCONTROL_NONE;
  huart2.Init.OverSampling = UART_OVERSAMPLING_16;
  if (HAL_UART_Init(&huart2) != HAL_OK)
  {
    Error_Handler();
  }

}

static void MX_USART3_UART_Init(void)
{

  huart3.Instance = USART3;
  huart3.Init.BaudRate = 115200;
  huart3.Init.WordLength = UART_WORDLENGTH_8B;
  huart3.Init.StopBits = UART_STOPBITS_1;
  huart3.Init.Parity = UART_PARITY_NONE;
  huart3.Init.Mode = UART_MODE_TX_RX;
  huart3.Init.HwFlowCtl = UART_HWCONTROL_NONE;
  huart3.Init.OverSampling = UART_OVERSAMPLING_16;
  if (HAL_UART_Init(&huart3) != HAL_OK)
  {
    Error_Handler();
  }

}

static void MX_USART6_UART_Init(void)
{

  huart6.Instance = USART6;
  huart6.Init.BaudRate = 115200;
  huart6.Init.WordLength = UART_WORDLENGTH_8B;
  huart6.Init.StopBits = UART_STOPBITS_1;
  huart6.Init.Parity = UART_PARITY_NONE;
  huart6.Init.Mode = UART_MODE_TX_RX;
  huart6.Init.HwFlowCtl = UART_HWCONTROL_NONE;
  huart6.Init.OverSampling = UART_OVERSAMPLING_16;
  if (HAL_UART_Init(&huart6) != HAL_OK)
  {
    Error_Handler();
  }

}

static void MX_DMA_Init(void)
{

  /* DMA controller clock enable */
  __HAL_RCC_DMA2_CLK_ENABLE();

  /* DMA interrupt init */
  /* DMA2_Stream0_IRQn interrupt configuration */
  HAL_NVIC_SetPriority(DMA2_Stream0_IRQn, 0, 0);
  HAL_NVIC_EnableIRQ(DMA2_Stream0_IRQn);

}

static void MX_GPIO_Init(void)
{
  GPIO_InitTypeDef GPIO_InitStruct = {0};

  /* GPIO Ports Clock Enable */
  __HAL_RCC_GPIOE_CLK_ENABLE();
  __HAL_RCC_GPIOC_CLK_ENABLE();
  __HAL_RCC_GPIOF_CLK_ENABLE();
  __HAL_RCC_GPIOH_CLK_ENABLE();
  __HAL_RCC_GPIOA_CLK_ENABLE();
  __HAL_RCC_GPIOG_CLK_ENABLE();
  __HAL_RCC_GPIOB_CLK_ENABLE();
  __HAL_RCC_GPIOD_CLK_ENABLE();

  /*Configure GPIO pin Output Level */
  HAL_GPIO_WritePin(GPIOC, STATE_LED0_Pin|STATE_LED1_Pin|STATE_LED2_Pin, GPIO_PIN_RESET);

  /*Configure GPIO pin Output Level */
  HAL_GPIO_WritePin(SPI2_NSS_GPIO_Port, SPI2_NSS_Pin, GPIO_PIN_RESET);

  /*Configure GPIO pin Output Level */
  HAL_GPIO_WritePin(GPIOA, FAN1_ONOFF_Pin|FAN2_ONOFF_Pin, GPIO_PIN_RESET);

  /*Configure GPIO pin Output Level */
  HAL_GPIO_WritePin(WIZNET_RESET_GPIO_Port, WIZNET_RESET_Pin, GPIO_PIN_SET);

  /*Configure GPIO pin Output Level */
  HAL_GPIO_WritePin(GPIOE, NBL0_Pin|NBL1_Pin, GPIO_PIN_RESET);

  /*Configure GPIO pins : FAN_A2_SENSOR_Pin FAN_B1_SENSOR_Pin */
  GPIO_InitStruct.Pin = FAN_A2_SENSOR_Pin|FAN_B1_SENSOR_Pin;
  GPIO_InitStruct.Mode = GPIO_MODE_IT_RISING;
  GPIO_InitStruct.Pull = GPIO_NOPULL;
  HAL_GPIO_Init(GPIOE, &GPIO_InitStruct);

  /*Configure GPIO pins : STATE_LED0_Pin STATE_LED1_Pin STATE_LED2_Pin */
  GPIO_InitStruct.Pin = STATE_LED0_Pin|STATE_LED1_Pin|STATE_LED2_Pin;
  GPIO_InitStruct.Mode = GPIO_MODE_OUTPUT_PP;
  GPIO_InitStruct.Pull = GPIO_NOPULL;
  GPIO_InitStruct.Speed = GPIO_SPEED_FREQ_LOW;
  HAL_GPIO_Init(GPIOC, &GPIO_InitStruct);

  /*Configure GPIO pins : STM32_GPS_PPS_Pin STM32_INS_PPS_Pin */
  GPIO_InitStruct.Pin = STM32_GPS_PPS_Pin|STM32_INS_PPS_Pin;
  GPIO_InitStruct.Mode = GPIO_MODE_IT_RISING;
  GPIO_InitStruct.Pull = GPIO_NOPULL;
  HAL_GPIO_Init(GPIOA, &GPIO_InitStruct);

  /*Configure GPIO pin : SPI2_NSS_Pin */
  GPIO_InitStruct.Pin = SPI2_NSS_Pin;
  GPIO_InitStruct.Mode = GPIO_MODE_OUTPUT_PP;
  GPIO_InitStruct.Pull = GPIO_NOPULL;
  GPIO_InitStruct.Speed = GPIO_SPEED_FREQ_LOW;
  HAL_GPIO_Init(SPI2_NSS_GPIO_Port, &GPIO_InitStruct);

  /*Configure GPIO pins : FAN1_ONOFF_Pin FAN2_ONOFF_Pin */
  GPIO_InitStruct.Pin = FAN1_ONOFF_Pin|FAN2_ONOFF_Pin;
  GPIO_InitStruct.Mode = GPIO_MODE_OUTPUT_PP;
  GPIO_InitStruct.Pull = GPIO_NOPULL;
  GPIO_InitStruct.Speed = GPIO_SPEED_FREQ_LOW;
  HAL_GPIO_Init(GPIOA, &GPIO_InitStruct);

  /*Configure GPIO pin : FAN_A1_SENSOR_Pin */
  GPIO_InitStruct.Pin = FAN_A1_SENSOR_Pin;
  GPIO_InitStruct.Mode = GPIO_MODE_IT_RISING;
  GPIO_InitStruct.Pull = GPIO_NOPULL;
  HAL_GPIO_Init(FAN_A1_SENSOR_GPIO_Port, &GPIO_InitStruct);

  /*Configure GPIO pin : WIZNET_RESET_Pin */
  GPIO_InitStruct.Pin = WIZNET_RESET_Pin;
  GPIO_InitStruct.Mode = GPIO_MODE_OUTPUT_PP;
  GPIO_InitStruct.Pull = GPIO_NOPULL;
  GPIO_InitStruct.Speed = GPIO_SPEED_FREQ_LOW;
  HAL_GPIO_Init(WIZNET_RESET_GPIO_Port, &GPIO_InitStruct);

  /*Configure GPIO pin : FAN_B2_SENSOR_Pin */
  GPIO_InitStruct.Pin = FAN_B2_SENSOR_Pin;
  GPIO_InitStruct.Mode = GPIO_MODE_IT_RISING;
  GPIO_InitStruct.Pull = GPIO_NOPULL;
  HAL_GPIO_Init(FAN_B2_SENSOR_GPIO_Port, &GPIO_InitStruct);

  /*Configure GPIO pins : NBL0_Pin NBL1_Pin */
  GPIO_InitStruct.Pin = NBL0_Pin|NBL1_Pin;
  GPIO_InitStruct.Mode = GPIO_MODE_OUTPUT_PP;
  GPIO_InitStruct.Pull = GPIO_NOPULL;
  GPIO_InitStruct.Speed = GPIO_SPEED_FREQ_LOW;
  HAL_GPIO_Init(GPIOE, &GPIO_InitStruct);

  /* EXTI interrupt init*/
  HAL_NVIC_SetPriority(EXTI2_IRQn, 0, 0);
  HAL_NVIC_EnableIRQ(EXTI2_IRQn);

  HAL_NVIC_SetPriority(EXTI3_IRQn, 0, 0);
  HAL_NVIC_EnableIRQ(EXTI3_IRQn);

  HAL_NVIC_SetPriority(EXTI9_5_IRQn, 0, 0);
  HAL_NVIC_EnableIRQ(EXTI9_5_IRQn);

  HAL_NVIC_SetPriority(EXTI15_10_IRQn, 0, 0);
  HAL_NVIC_EnableIRQ(EXTI15_10_IRQn);

}

/* FSMC initialization function */
static void MX_FSMC_Init(void)
{

  FSMC_NORSRAM_TimingTypeDef Timing = {0};

  /** Perform the SRAM2 memory initialization sequence
  */
  hsram2.Instance = FSMC_NORSRAM_DEVICE;
  hsram2.Extended = FSMC_NORSRAM_EXTENDED_DEVICE;
  /* hsram2.Init */
  hsram2.Init.NSBank = FSMC_NORSRAM_BANK2;
  hsram2.Init.DataAddressMux = FSMC_DATA_ADDRESS_MUX_DISABLE;
  hsram2.Init.MemoryType = FSMC_MEMORY_TYPE_SRAM;
  hsram2.Init.MemoryDataWidth = FSMC_NORSRAM_MEM_BUS_WIDTH_16;
  hsram2.Init.BurstAccessMode = FSMC_BURST_ACCESS_MODE_DISABLE;
  hsram2.Init.WaitSignalPolarity = FSMC_WAIT_SIGNAL_POLARITY_LOW;
  hsram2.Init.WrapMode = FSMC_WRAP_MODE_DISABLE;
  hsram2.Init.WaitSignalActive = FSMC_WAIT_TIMING_BEFORE_WS;
  hsram2.Init.WriteOperation = FSMC_WRITE_OPERATION_ENABLE;
  hsram2.Init.WaitSignal = FSMC_WAIT_SIGNAL_DISABLE;
  hsram2.Init.ExtendedMode = FSMC_EXTENDED_MODE_DISABLE;
  hsram2.Init.AsynchronousWait = FSMC_ASYNCHRONOUS_WAIT_DISABLE;
  hsram2.Init.WriteBurst = FSMC_WRITE_BURST_DISABLE;
  hsram2.Init.PageSize = FSMC_PAGE_SIZE_NONE;
  /* Timing */
  Timing.AddressSetupTime = 0;
  Timing.AddressHoldTime = 15;
  Timing.DataSetupTime = 3;
  Timing.BusTurnAroundDuration = 0;
  Timing.CLKDivision = 16;
  Timing.DataLatency = 17;
  Timing.AccessMode = FSMC_ACCESS_MODE_A;
  /* ExtTiming */

  if (HAL_SRAM_Init(&hsram2, &Timing, NULL) != HAL_OK)
  {
    Error_Handler( );
  }

}

void Error_Handler(void)
{
  __disable_irq();
  while (1)
  {
  }
}
